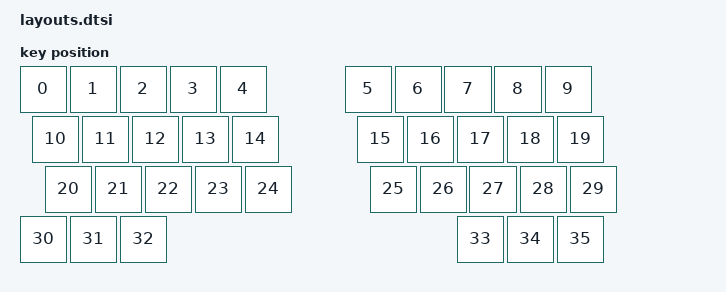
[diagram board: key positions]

#include <physical_layouts.dtsi>
/ {
    physical_layout0: physical_layout0 {
        compatible = "zmk,physical-layout";
        display-name = "Layout";
        keys
            = <&key_physical_attrs 100 100 (-50) 13 0 0 0>
			,<&key_physical_attrs 100 100 50 13 0 0 0>
			,<&key_physical_attrs 100 100 150 13 0 0 0>
			,<&key_physical_attrs 100 100 250 13 0 0 0>
			,<&key_physical_attrs 100 100 350 13 0 0 0>
			,<&key_physical_attrs 100 100 600 13 0 0 0>
			,<&key_physical_attrs 100 100 700 13 0 0 0>
			,<&key_physical_attrs 100 100 800 13 0 0 0>
			,<&key_physical_attrs 100 100 900 13 0 0 0>
			,<&key_physical_attrs 100 100 1000 13 0 0 0>
			,<&key_physical_attrs 100 100 (-25) 113 0 0 0>
			,<&key_physical_attrs 100 100 75 113 0 0 0>
			,<&key_physical_attrs 100 100 175 113 0 0 0>
			,<&key_physical_attrs 100 100 275 113 0 0 0>
			,<&key_physical_attrs 100 100 375 113 0 0 0>
			,<&key_physical_attrs 100 100 625 113 0 0 0>
			,<&key_physical_attrs 100 100 725 113 0 0 0>
			,<&key_physical_attrs 100 100 825 113 0 0 0>
			,<&key_physical_attrs 100 100 925 113 0 0 0>
			,<&key_physical_attrs 100 100 1025 113 0 0 0>
			,<&key_physical_attrs 100 100 0 213 0 0 0>
			,<&key_physical_attrs 100 100 100 213 0 0 0>
			,<&key_physical_attrs 100 100 200 213 0 0 0>
			,<&key_physical_attrs 100 100 300 213 0 0 0>
			,<&key_physical_attrs 100 100 400 213 0 0 0>
			,<&key_physical_attrs 100 100 650 213 0 0 0>
			,<&key_physical_attrs 100 100 750 213 0 0 0>
			,<&key_physical_attrs 100 100 850 213 0 0 0>
			,<&key_physical_attrs 100 100 950 213 0 0 0>
			,<&key_physical_attrs 100 100 1050 213 0 0 0>
			,<&key_physical_attrs 100 100 (-50) 313 0 0 0>
			,<&key_physical_attrs 100 100 50 313 0 0 0>
			,<&key_physical_attrs 100 100 150 313 0 0 0>
			,<&key_physical_attrs 100 100 825 313 0 0 0>
			,<&key_physical_attrs 100 100 925 313 0 0 0>
			,<&key_physical_attrs 100 100 1025 313 0 0 0>
            ;
    };
};
    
